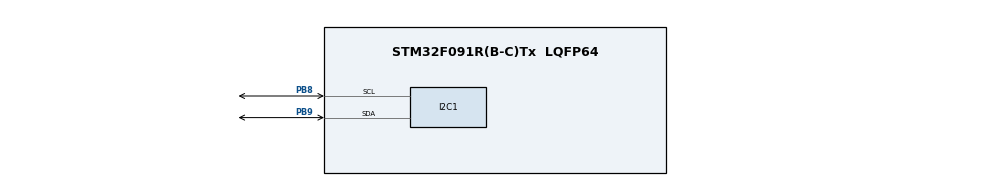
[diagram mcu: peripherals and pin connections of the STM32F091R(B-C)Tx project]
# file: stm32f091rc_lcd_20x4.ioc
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I2C1.Timing=0x00201D2B
Mcu.Family=STM32F0
Mcu.Name=STM32F091R(B-C)Tx
Mcu.Package=LQFP64
PB8.Mode=I2C
PB8.Signal=I2C1_SCL
PB9.Mode=I2C
PB9.Signal=I2C1_SDA
ProjectManager.HeapSize=0x200
ProjectManager.StackSize=0x400
ProjectManager.TargetToolchain=CMake
board=custom

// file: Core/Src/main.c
/* USER CODE BEGIN Header */
/**
  ******************************************************************************
  * @file           : main.c
  * @brief          : Main program body
  ******************************************************************************
  * @attention
  *
  * Copyright (c) 2025 STMicroelectronics.
  * All rights reserved.
  *
  * This software is licensed under terms that can be found in the LICENSE file
  * in the root directory of this software component.
  * If no LICENSE file comes with this software, it is provided AS-IS.
  *
  ******************************************************************************
  */
/* USER CODE END Header */
#include "main.h"

/* USER CODE BEGIN Includes */
#include "lcd_i2c_driver.h"
/* USER CODE END Includes */

I2C_HandleTypeDef hi2c1;

/* USER CODE BEGIN PV */
LCD_Handle lcd;
LCD_Animation arrow_anim;
/* USER CODE END PV */

void SystemClock_Config(void);
static void MX_GPIO_Init(void);
static void MX_I2C1_Init(void);

int main(void)
{

  /* MCU Configuration--------------------------------------------------------*/

  /* Reset of all peripherals, Initializes the Flash interface and the Systick. */
  HAL_Init();

  /* Configure the system clock */
  SystemClock_Config();

  /* Initialize all configured peripherals */
  MX_GPIO_Init();
  MX_I2C1_Init();
  /* USER CODE BEGIN 2 */
  // Initialize LCD
    if (LCD_Init(&lcd, &hi2c1) != HAL_OK) {
      Error_Handler();
    }

  // Welcome screen
  LCD_Clear(&lcd);
  LCD_PrintAt(&lcd, 0, 0, "  LCD Test  ");
  LCD_PrintAt(&lcd, 1, 0, "STM32F091RC");
  LCD_DrawSeparator(&lcd, 2);
  LCD_PrintAt(&lcd, 3, 0, "Initializing...");
  HAL_Delay(2000);

  // Initialize arrow animation
  LCD_InitAnimation(&arrow_anim, ANIM_ARROW_RIGHT, 0, 0, 200);

  uint8_t demo_step = 0;
  uint32_t last_update = 0;
  /* USER CODE END 2 */

  /* Infinite loop */
  /* USER CODE BEGIN WHILE */
  while (1)
  {
    // Update animation
        LCD_UpdateAnimation(&lcd, &arrow_anim);

        // Change demo every 5 seconds
        if (HAL_GetTick() - last_update > 5000) {
            last_update = HAL_GetTick();
            demo_step = (demo_step + 1) % 4;

            LCD_Clear(&lcd);

            switch (demo_step) {
                case 0:
                    // Menu simulation
                    LCD_PrintAt(&lcd, 0, 2, "Main Menu");
                    LCD_DrawSeparator(&lcd, 1);
                    LCD_PrintCustomChar(&lcd, CHAR_ARROW_RIGHT);
                    LCD_PrintAt(&lcd, 2, 2, "View Sensors");
                    LCD_PrintAt(&lcd, 3, 2, "Settings");
                    arrow_anim.type = ANIM_ARROW_RIGHT;
                    arrow_anim.row = 2;
                    arrow_anim.col = 0;
                    break;

                case 1:
                    // Progress bar demo
                    LCD_PrintAt(&lcd, 0, 0, "Loading Data...");
                    for (uint8_t i = 0; i <= 100; i += 10) {
                        LCD_DrawProgressBar(&lcd, 2, 0, 15, i);
                        HAL_Delay(300);
                    }
                    break;

                case 2:
                    // Spinner demo
                    LCD_PrintAt(&lcd, 0, 0, "Processing");
                    arrow_anim.type = ANIM_SPINNER;
                    arrow_anim.row = 0;
                    arrow_anim.col = 11;
                    arrow_anim.speed = 100;
                    break;

                case 3:
                    // Custom characters
                    LCD_PrintAt(&lcd, 0, 0, "Custom Chars:");
                    LCD_SetCursor(&lcd, 1, 0);
                    LCD_PrintCustomChar(&lcd, CHAR_ARROW_RIGHT);
                    LCD_Print(&lcd, " ");
                    LCD_PrintCustomChar(&lcd, CHAR_ARROW_LEFT);
                    LCD_Print(&lcd, " ");
                    LCD_PrintCustomChar(&lcd, CHAR_HEART);
                    LCD_Print(&lcd, " ");
                    LCD_PrintCustomChar(&lcd, CHAR_BELL);

                    LCD_PrintAt(&lcd, 2, 0, "Temp: 25");
                    LCD_PrintCustomChar(&lcd, CHAR_DEGREE);
                    LCD_Print(&lcd, "C");

                    LCD_PrintAt(&lcd, 3, 0, "Battery: ");
                    LCD_PrintCustomChar(&lcd, CHAR_BATTERY_FULL);
                    break;
            }
        }

        HAL_Delay(50);
    /* USER CODE END WHILE */

  }
}

void SystemClock_Config(void)
{
  RCC_OscInitTypeDef RCC_OscInitStruct = {0};
  RCC_ClkInitTypeDef RCC_ClkInitStruct = {0};
  RCC_PeriphCLKInitTypeDef PeriphClkInit = {0};

  /** Initializes the RCC Oscillators according to the specified parameters
  * in the RCC_OscInitTypeDef structure.
  */
  RCC_OscInitStruct.OscillatorType = RCC_OSCILLATORTYPE_HSI;
  RCC_OscInitStruct.HSIState = RCC_HSI_ON;
  RCC_OscInitStruct.HSICalibrationValue = RCC_HSICALIBRATION_DEFAULT;
  RCC_OscInitStruct.PLL.PLLState = RCC_PLL_NONE;
  if (HAL_RCC_OscConfig(&RCC_OscInitStruct) != HAL_OK)
  {
    Error_Handler();
  }

  /** Initializes the CPU, AHB and APB buses clocks
  */
  RCC_ClkInitStruct.ClockType = RCC_CLOCKTYPE_HCLK|RCC_CLOCKTYPE_SYSCLK
                              |RCC_CLOCKTYPE_PCLK1;
  RCC_ClkInitStruct.SYSCLKSource = RCC_SYSCLKSOURCE_HSI;
  RCC_ClkInitStruct.AHBCLKDivider = RCC_SYSCLK_DIV1;
  RCC_ClkInitStruct.APB1CLKDivider = RCC_HCLK_DIV1;

  if (HAL_RCC_ClockConfig(&RCC_ClkInitStruct, FLASH_LATENCY_0) != HAL_OK)
  {
    Error_Handler();
  }
  PeriphClkInit.PeriphClockSelection = RCC_PERIPHCLK_I2C1;
  PeriphClkInit.I2c1ClockSelection = RCC_I2C1CLKSOURCE_HSI;
  if (HAL_RCCEx_PeriphCLKConfig(&PeriphClkInit) != HAL_OK)
  {
    Error_Handler();
  }
}

static void MX_I2C1_Init(void)
{

  hi2c1.Instance = I2C1;
  hi2c1.Init.Timing = 0x00201D2B;
  hi2c1.Init.OwnAddress1 = 0;
  hi2c1.Init.AddressingMode = I2C_ADDRESSINGMODE_7BIT;
  hi2c1.Init.DualAddressMode = I2C_DUALADDRESS_DISABLE;
  hi2c1.Init.OwnAddress2 = 0;
  hi2c1.Init.OwnAddress2Masks = I2C_OA2_NOMASK;
  hi2c1.Init.GeneralCallMode = I2C_GENERALCALL_DISABLE;
  hi2c1.Init.NoStretchMode = I2C_NOSTRETCH_DISABLE;
  if (HAL_I2C_Init(&hi2c1) != HAL_OK)
  {
    Error_Handler();
  }

  /** Configure Analogue filter
  */
  if (HAL_I2CEx_ConfigAnalogFilter(&hi2c1, I2C_ANALOGFILTER_ENABLE) != HAL_OK)
  {
    Error_Handler();
  }

  /** Configure Digital filter
  */
  if (HAL_I2CEx_ConfigDigitalFilter(&hi2c1, 0) != HAL_OK)
  {
    Error_Handler();
  }

}

static void MX_GPIO_Init(void)
{

  /* GPIO Ports Clock Enable */
  __HAL_RCC_GPIOB_CLK_ENABLE();

}

void Error_Handler(void)
{
  __disable_irq();
  while (1)
  {
  }
}
